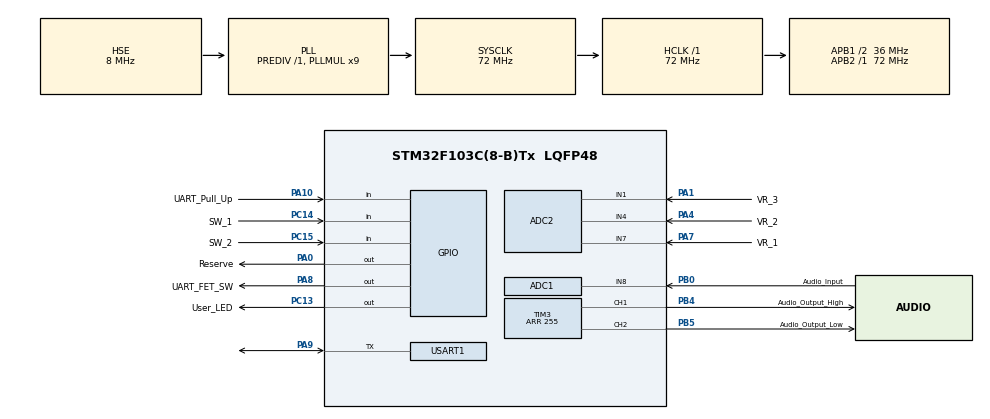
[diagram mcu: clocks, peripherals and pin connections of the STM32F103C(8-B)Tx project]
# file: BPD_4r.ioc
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ADC1.Channel-0\#ChannelRegularConversion=ADC_CHANNEL_8
ADC1.ExternalTrigConv=ADC_EXTERNALTRIGCONV_T2_CC2
ADC1.NbrOfConversionFlag=1
ADC1.Rank-0\#ChannelRegularConversion=1
ADC1.SamplingTime-0\#ChannelRegularConversion=ADC_SAMPLETIME_1CYCLE_5
ADC1.master=1
ADC2.Channel-0\#ChannelRegularConversion=ADC_CHANNEL_1
ADC2.Channel-2\#ChannelRegularConversion=ADC_CHANNEL_4
ADC2.Channel-3\#ChannelRegularConversion=ADC_CHANNEL_7
ADC2.DiscontinuousConvMode=ENABLE
ADC2.NbrOfConversion=3
ADC2.NbrOfConversionFlag=1
ADC2.Rank-0\#ChannelRegularConversion=1
ADC2.Rank-2\#ChannelRegularConversion=2
ADC2.Rank-3\#ChannelRegularConversion=3
ADC2.SamplingTime-0\#ChannelRegularConversion=ADC_SAMPLETIME_71CYCLES_5
ADC2.SamplingTime-2\#ChannelRegularConversion=ADC_SAMPLETIME_71CYCLES_5
ADC2.SamplingTime-3\#ChannelRegularConversion=ADC_SAMPLETIME_239CYCLES_5
Dma.ADC1.0.Direction=DMA_PERIPH_TO_MEMORY
Dma.ADC1.0.Instance=DMA1_Channel1
Dma.ADC1.0.MemDataAlignment=DMA_MDATAALIGN_HALFWORD
Dma.ADC1.0.MemInc=DMA_MINC_ENABLE
Dma.ADC1.0.Mode=DMA_CIRCULAR
Dma.ADC1.0.PeriphDataAlignment=DMA_PDATAALIGN_HALFWORD
Dma.ADC1.0.PeriphInc=DMA_PINC_DISABLE
Dma.ADC1.0.Priority=DMA_PRIORITY_VERY_HIGH
Dma.Request0=ADC1
Mcu.Family=STM32F1
Mcu.Name=STM32F103C(8-B)Tx
Mcu.Package=LQFP48
NVIC.ADC1_2_IRQn=true\:0\:0\:false\:false\:true\:true\:true
NVIC.DMA1_Channel1_IRQn=true\:0\:0\:false\:false\:true\:false\:true
NVIC.PriorityGroup=NVIC_PRIORITYGROUP_4
NVIC.USART1_IRQn=true\:2\:0\:true\:false\:true\:true\:true
PA0-WKUP.GPIO_Label=Reserve
PA0-WKUP.GPIO_ModeDefaultOutputPP=GPIO_MODE_OUTPUT_OD
PA0-WKUP.GPIO_PuPd=GPIO_PULLUP
PA0-WKUP.PinState=GPIO_PIN_SET
PA0-WKUP.Signal=GPIO_Output
PA1.GPIO_Label=VR_3
PA1.Signal=ADCx_IN1
PA10.GPIO_Label=UART_Pull_Up
PA10.GPIO_PuPd=GPIO_PULLUP
PA10.Signal=GPIO_Input
PA13.Mode=Serial_Wire
PA13.Signal=SYS_JTMS-SWDIO
PA14.Mode=Serial_Wire
PA14.Signal=SYS_JTCK-SWCLK
PA4.GPIO_Label=VR_2
PA4.Signal=ADCx_IN4
PA7.GPIO_Label=VR_1
PA7.Signal=ADCx_IN7
PA8.GPIO_Label=UART_FET_SW
PA8.Signal=GPIO_Output
PA9.Mode=Half_duplex(single_wire_mode)
PA9.Signal=USART1_TX
PB0.GPIO_Label=Audio_Input
PB0.Signal=ADCx_IN8
PB4.GPIO_Label=Audio_Output_High
PB4.GPIO_Speed=GPIO_SPEED_FREQ_HIGH
PB4.Signal=S_TIM3_CH1
PB5.GPIO_Label=Audio_Output_Low
PB5.GPIO_Speed=GPIO_SPEED_FREQ_HIGH
PB5.Signal=S_TIM3_CH2
PC13-TAMPER-RTC.GPIO_Label=User_LED
PC13-TAMPER-RTC.PinState=GPIO_PIN_SET
PC13-TAMPER-RTC.Signal=GPIO_Output
PC14-OSC32_IN.GPIO_Label=SW_1
PC14-OSC32_IN.GPIO_PuPd=GPIO_PULLUP
PC14-OSC32_IN.Signal=GPIO_Input
PC15-OSC32_OUT.GPIO_Label=SW_2
PC15-OSC32_OUT.GPIO_PuPd=GPIO_PULLUP
PC15-OSC32_OUT.Signal=GPIO_Input
PD0-OSC_IN.Mode=HSE-External-Oscillator
PD0-OSC_IN.Signal=RCC_OSC_IN
PD1-OSC_OUT.Mode=HSE-External-Oscillator
PD1-OSC_OUT.Signal=RCC_OSC_OUT
ProjectManager.HeapSize=0x200
ProjectManager.StackSize=0x400
ProjectManager.TargetToolchain=STM32CubeIDE
RCC.AHBFreq_Value=72000000
RCC.APB1CLKDivider=RCC_HCLK_DIV2
RCC.APB1Freq_Value=36000000
RCC.APB1TimFreq_Value=72000000
RCC.APB2Freq_Value=72000000
RCC.APB2TimFreq_Value=72000000
RCC.HCLKFreq_Value=72000000
RCC.PLLMUL=RCC_PLL_MUL9
RCC.PLLSourceVirtual=RCC_PLLSOURCE_HSE
RCC.SYSCLKFreq_VALUE=72000000
RCC.SYSCLKSource=RCC_SYSCLKSOURCE_PLLCLK
RCC.USBFreq_Value=72000000
SH.ADCx_IN1.0=ADC2_IN1,IN1
SH.ADCx_IN4.0=ADC2_IN4,IN4
SH.ADCx_IN7.0=ADC2_IN7,IN7
SH.ADCx_IN8.0=ADC1_IN8,IN8
SH.S_TIM3_CH1.0=TIM3_CH1,PWM Generation1 CH1
SH.S_TIM3_CH2.0=TIM3_CH2,PWM Generation2 CH2
TIM2.Channel-Output\ Compare2\ No\ Output=TIM_CHANNEL_2
TIM2.OCMode_2=TIM_OCMODE_TOGGLE
TIM2.OCPolarity_2=TIM_OCPOLARITY_LOW
TIM2.Period=17
TIM2.TIM_MasterOutputTrigger=TIM_TRGO_OC2REF
TIM3.Channel-PWM\ Generation1\ CH1=TIM_CHANNEL_1
TIM3.Channel-PWM\ Generation2\ CH2=TIM_CHANNEL_2
TIM3.OCFastMode_PWM-PWM\ Generation1\ CH1=TIM_OCFAST_ENABLE
TIM3.OCFastMode_PWM-PWM\ Generation2\ CH2=TIM_OCFAST_ENABLE
TIM3.Period=255
USART1.BaudRate=9600
USART1.VirtualMode=VM_ASYNC
VP_TIM2_VS_no_output2.Mode=Output Compare2 No Output
board=custom

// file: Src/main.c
/* USER CODE BEGIN Header */
/**
  ******************************************************************************
  * @file           : main.c
  * @brief          : Main program body
  ******************************************************************************
  * @attention
  *
  * <h2><center>&copy; Copyright (c) 2019 STMicroelectronics.
  * All rights reserved.</center></h2>
  *
  * This software component is licensed by ST under BSD 3-Clause license,
  * the "License"; You may not use this file except in compliance with the
  * License. You may obtain a copy of the License at:
  *                        opensource.org/licenses/BSD-3-Clause
  *
  ******************************************************************************
  */
/* USER CODE END Header */

#include "main.h"

ADC_HandleTypeDef hadc1;
ADC_HandleTypeDef hadc2;
DMA_HandleTypeDef hdma_adc1;

TIM_HandleTypeDef htim2;
TIM_HandleTypeDef htim3;

UART_HandleTypeDef huart1;

void SystemClock_Config(void);
static void MX_GPIO_Init(void);
static void MX_DMA_Init(void);
static void MX_ADC1_Init(void);
static void MX_ADC2_Init(void);
static void MX_TIM2_Init(void);
static void MX_TIM3_Init(void);
static void MX_USART1_UART_Init(void);
/* USER CODE BEGIN PFP */
void main_cpp();
/* USER CODE END PFP */

int main(void)
{

  /* MCU Configuration--------------------------------------------------------*/

  /* Reset of all peripherals, Initializes the Flash interface and the Systick. */
  HAL_Init();

  /* Configure the system clock */
  SystemClock_Config();

  /* Initialize all configured peripherals */
  MX_GPIO_Init();
  MX_DMA_Init();
  MX_ADC1_Init();
  MX_ADC2_Init();
  MX_TIM2_Init();
  MX_TIM3_Init();
  MX_USART1_UART_Init();

  /* Infinite loop */
  /* USER CODE BEGIN WHILE */
//  while (1)
  {
  	main_cpp();
    /* USER CODE END WHILE */

  }
}

void SystemClock_Config(void)
{
  RCC_OscInitTypeDef RCC_OscInitStruct = {0};
  RCC_ClkInitTypeDef RCC_ClkInitStruct = {0};
  RCC_PeriphCLKInitTypeDef PeriphClkInit = {0};

  /** Initializes the CPU, AHB and APB busses clocks
  */
  RCC_OscInitStruct.OscillatorType = RCC_OSCILLATORTYPE_HSE;
  RCC_OscInitStruct.HSEState = RCC_HSE_ON;
  RCC_OscInitStruct.HSEPredivValue = RCC_HSE_PREDIV_DIV1;
  RCC_OscInitStruct.HSIState = RCC_HSI_ON;
  RCC_OscInitStruct.PLL.PLLState = RCC_PLL_ON;
  RCC_OscInitStruct.PLL.PLLSource = RCC_PLLSOURCE_HSE;
  RCC_OscInitStruct.PLL.PLLMUL = RCC_PLL_MUL9;
  if (HAL_RCC_OscConfig(&RCC_OscInitStruct) != HAL_OK)
  {
    Error_Handler();
  }
  /** Initializes the CPU, AHB and APB busses clocks
  */
  RCC_ClkInitStruct.ClockType = RCC_CLOCKTYPE_HCLK|RCC_CLOCKTYPE_SYSCLK
                              |RCC_CLOCKTYPE_PCLK1|RCC_CLOCKTYPE_PCLK2;
  RCC_ClkInitStruct.SYSCLKSource = RCC_SYSCLKSOURCE_PLLCLK;
  RCC_ClkInitStruct.AHBCLKDivider = RCC_SYSCLK_DIV1;
  RCC_ClkInitStruct.APB1CLKDivider = RCC_HCLK_DIV2;
  RCC_ClkInitStruct.APB2CLKDivider = RCC_HCLK_DIV1;

  if (HAL_RCC_ClockConfig(&RCC_ClkInitStruct, FLASH_LATENCY_2) != HAL_OK)
  {
    Error_Handler();
  }
  PeriphClkInit.PeriphClockSelection = RCC_PERIPHCLK_ADC;
  PeriphClkInit.AdcClockSelection = RCC_ADCPCLK2_DIV2;
  if (HAL_RCCEx_PeriphCLKConfig(&PeriphClkInit) != HAL_OK)
  {
    Error_Handler();
  }
}

static void MX_ADC1_Init(void)
{

  ADC_ChannelConfTypeDef sConfig = {0};

  /** Common config
  */
  hadc1.Instance = ADC1;
  hadc1.Init.ScanConvMode = ADC_SCAN_DISABLE;
  hadc1.Init.ContinuousConvMode = DISABLE;
  hadc1.Init.DiscontinuousConvMode = DISABLE;
  hadc1.Init.ExternalTrigConv = ADC_EXTERNALTRIGCONV_T2_CC2;
  hadc1.Init.DataAlign = ADC_DATAALIGN_RIGHT;
  hadc1.Init.NbrOfConversion = 1;
  if (HAL_ADC_Init(&hadc1) != HAL_OK)
  {
    Error_Handler();
  }
  /** Configure Regular Channel
  */
  sConfig.Channel = ADC_CHANNEL_8;
  sConfig.Rank = ADC_REGULAR_RANK_1;
  sConfig.SamplingTime = ADC_SAMPLETIME_1CYCLE_5;
  if (HAL_ADC_ConfigChannel(&hadc1, &sConfig) != HAL_OK)
  {
    Error_Handler();
  }

}

static void MX_ADC2_Init(void)
{

  ADC_ChannelConfTypeDef sConfig = {0};

  /** Common config
  */
  hadc2.Instance = ADC2;
  hadc2.Init.ScanConvMode = ADC_SCAN_ENABLE;
  hadc2.Init.ContinuousConvMode = DISABLE;
  hadc2.Init.DiscontinuousConvMode = ENABLE;
  hadc2.Init.NbrOfDiscConversion = 1;
  hadc2.Init.ExternalTrigConv = ADC_SOFTWARE_START;
  hadc2.Init.DataAlign = ADC_DATAALIGN_RIGHT;
  hadc2.Init.NbrOfConversion = 3;
  if (HAL_ADC_Init(&hadc2) != HAL_OK)
  {
    Error_Handler();
  }
  /** Configure Regular Channel
  */
  sConfig.Channel = ADC_CHANNEL_1;
  sConfig.Rank = ADC_REGULAR_RANK_1;
  sConfig.SamplingTime = ADC_SAMPLETIME_71CYCLES_5;
  if (HAL_ADC_ConfigChannel(&hadc2, &sConfig) != HAL_OK)
  {
    Error_Handler();
  }
  /** Configure Regular Channel
  */
  sConfig.Channel = ADC_CHANNEL_4;
  sConfig.Rank = ADC_REGULAR_RANK_2;
  if (HAL_ADC_ConfigChannel(&hadc2, &sConfig) != HAL_OK)
  {
    Error_Handler();
  }
  /** Configure Regular Channel
  */
  sConfig.Channel = ADC_CHANNEL_7;
  sConfig.Rank = ADC_REGULAR_RANK_3;
  sConfig.SamplingTime = ADC_SAMPLETIME_239CYCLES_5;
  if (HAL_ADC_ConfigChannel(&hadc2, &sConfig) != HAL_OK)
  {
    Error_Handler();
  }

}

static void MX_TIM2_Init(void)
{

  TIM_MasterConfigTypeDef sMasterConfig = {0};
  TIM_OC_InitTypeDef sConfigOC = {0};

  htim2.Instance = TIM2;
  htim2.Init.Prescaler = 0;
  htim2.Init.CounterMode = TIM_COUNTERMODE_UP;
  htim2.Init.Period = 17;
  htim2.Init.ClockDivision = TIM_CLOCKDIVISION_DIV1;
  htim2.Init.AutoReloadPreload = TIM_AUTORELOAD_PRELOAD_DISABLE;
  if (HAL_TIM_OC_Init(&htim2) != HAL_OK)
  {
    Error_Handler();
  }
  sMasterConfig.MasterOutputTrigger = TIM_TRGO_OC2REF;
  sMasterConfig.MasterSlaveMode = TIM_MASTERSLAVEMODE_DISABLE;
  if (HAL_TIMEx_MasterConfigSynchronization(&htim2, &sMasterConfig) != HAL_OK)
  {
    Error_Handler();
  }
  sConfigOC.OCMode = TIM_OCMODE_TOGGLE;
  sConfigOC.Pulse = 0;
  sConfigOC.OCPolarity = TIM_OCPOLARITY_LOW;
  sConfigOC.OCFastMode = TIM_OCFAST_DISABLE;
  if (HAL_TIM_OC_ConfigChannel(&htim2, &sConfigOC, TIM_CHANNEL_2) != HAL_OK)
  {
    Error_Handler();
  }

}

static void MX_TIM3_Init(void)
{

  TIM_MasterConfigTypeDef sMasterConfig = {0};
  TIM_OC_InitTypeDef sConfigOC = {0};

  htim3.Instance = TIM3;
  htim3.Init.Prescaler = 0;
  htim3.Init.CounterMode = TIM_COUNTERMODE_UP;
  htim3.Init.Period = 255;
  htim3.Init.ClockDivision = TIM_CLOCKDIVISION_DIV1;
  htim3.Init.AutoReloadPreload = TIM_AUTORELOAD_PRELOAD_DISABLE;
  if (HAL_TIM_PWM_Init(&htim3) != HAL_OK)
  {
    Error_Handler();
  }
  sMasterConfig.MasterOutputTrigger = TIM_TRGO_RESET;
  sMasterConfig.MasterSlaveMode = TIM_MASTERSLAVEMODE_DISABLE;
  if (HAL_TIMEx_MasterConfigSynchronization(&htim3, &sMasterConfig) != HAL_OK)
  {
    Error_Handler();
  }
  sConfigOC.OCMode = TIM_OCMODE_PWM1;
  sConfigOC.Pulse = 0;
  sConfigOC.OCPolarity = TIM_OCPOLARITY_HIGH;
  sConfigOC.OCFastMode = TIM_OCFAST_ENABLE;
  if (HAL_TIM_PWM_ConfigChannel(&htim3, &sConfigOC, TIM_CHANNEL_1) != HAL_OK)
  {
    Error_Handler();
  }
  if (HAL_TIM_PWM_ConfigChannel(&htim3, &sConfigOC, TIM_CHANNEL_2) != HAL_OK)
  {
    Error_Handler();
  }
  HAL_TIM_MspPostInit(&htim3);

}

static void MX_USART1_UART_Init(void)
{

  huart1.Instance = USART1;
  huart1.Init.BaudRate = 9600;
  huart1.Init.WordLength = UART_WORDLENGTH_8B;
  huart1.Init.StopBits = UART_STOPBITS_1;
  huart1.Init.Parity = UART_PARITY_NONE;
  huart1.Init.Mode = UART_MODE_TX_RX;
  huart1.Init.HwFlowCtl = UART_HWCONTROL_NONE;
  huart1.Init.OverSampling = UART_OVERSAMPLING_16;
  if (HAL_HalfDuplex_Init(&huart1) != HAL_OK)
  {
    Error_Handler();
  }

}

static void MX_DMA_Init(void)
{

  /* DMA controller clock enable */
  __HAL_RCC_DMA1_CLK_ENABLE();

  /* DMA interrupt init */
  /* DMA1_Channel1_IRQn interrupt configuration */
  HAL_NVIC_SetPriority(DMA1_Channel1_IRQn, 0, 0);
  HAL_NVIC_EnableIRQ(DMA1_Channel1_IRQn);

}

static void MX_GPIO_Init(void)
{
  GPIO_InitTypeDef GPIO_InitStruct = {0};

  /* GPIO Ports Clock Enable */
  __HAL_RCC_GPIOC_CLK_ENABLE();
  __HAL_RCC_GPIOD_CLK_ENABLE();
  __HAL_RCC_GPIOA_CLK_ENABLE();
  __HAL_RCC_GPIOB_CLK_ENABLE();

  /*Configure GPIO pin Output Level */
  HAL_GPIO_WritePin(User_LED_GPIO_Port, User_LED_Pin, GPIO_PIN_SET);

  /*Configure GPIO pin Output Level */
  HAL_GPIO_WritePin(Reserve_GPIO_Port, Reserve_Pin, GPIO_PIN_SET);

  /*Configure GPIO pin Output Level */
  HAL_GPIO_WritePin(UART_FET_SW_GPIO_Port, UART_FET_SW_Pin, GPIO_PIN_RESET);

  /*Configure GPIO pin : User_LED_Pin */
  GPIO_InitStruct.Pin = User_LED_Pin;
  GPIO_InitStruct.Mode = GPIO_MODE_OUTPUT_PP;
  GPIO_InitStruct.Pull = GPIO_NOPULL;
  GPIO_InitStruct.Speed = GPIO_SPEED_FREQ_LOW;
  HAL_GPIO_Init(User_LED_GPIO_Port, &GPIO_InitStruct);

  /*Configure GPIO pins : SW_1_Pin SW_2_Pin */
  GPIO_InitStruct.Pin = SW_1_Pin|SW_2_Pin;
  GPIO_InitStruct.Mode = GPIO_MODE_INPUT;
  GPIO_InitStruct.Pull = GPIO_PULLUP;
  HAL_GPIO_Init(GPIOC, &GPIO_InitStruct);

  /*Configure GPIO pin : Reserve_Pin */
  GPIO_InitStruct.Pin = Reserve_Pin;
  GPIO_InitStruct.Mode = GPIO_MODE_OUTPUT_OD;
  GPIO_InitStruct.Pull = GPIO_PULLUP;
  GPIO_InitStruct.Speed = GPIO_SPEED_FREQ_LOW;
  HAL_GPIO_Init(Reserve_GPIO_Port, &GPIO_InitStruct);

  /*Configure GPIO pin : UART_FET_SW_Pin */
  GPIO_InitStruct.Pin = UART_FET_SW_Pin;
  GPIO_InitStruct.Mode = GPIO_MODE_OUTPUT_PP;
  GPIO_InitStruct.Pull = GPIO_NOPULL;
  GPIO_InitStruct.Speed = GPIO_SPEED_FREQ_LOW;
  HAL_GPIO_Init(UART_FET_SW_GPIO_Port, &GPIO_InitStruct);

  /*Configure GPIO pin : UART_Pull_Up_Pin */
  GPIO_InitStruct.Pin = UART_Pull_Up_Pin;
  GPIO_InitStruct.Mode = GPIO_MODE_INPUT;
  GPIO_InitStruct.Pull = GPIO_PULLUP;
  HAL_GPIO_Init(UART_Pull_Up_GPIO_Port, &GPIO_InitStruct);

}

void Error_Handler(void)
{
}

/************************ (C) COPYRIGHT STMicroelectronics *****END OF FILE****/
